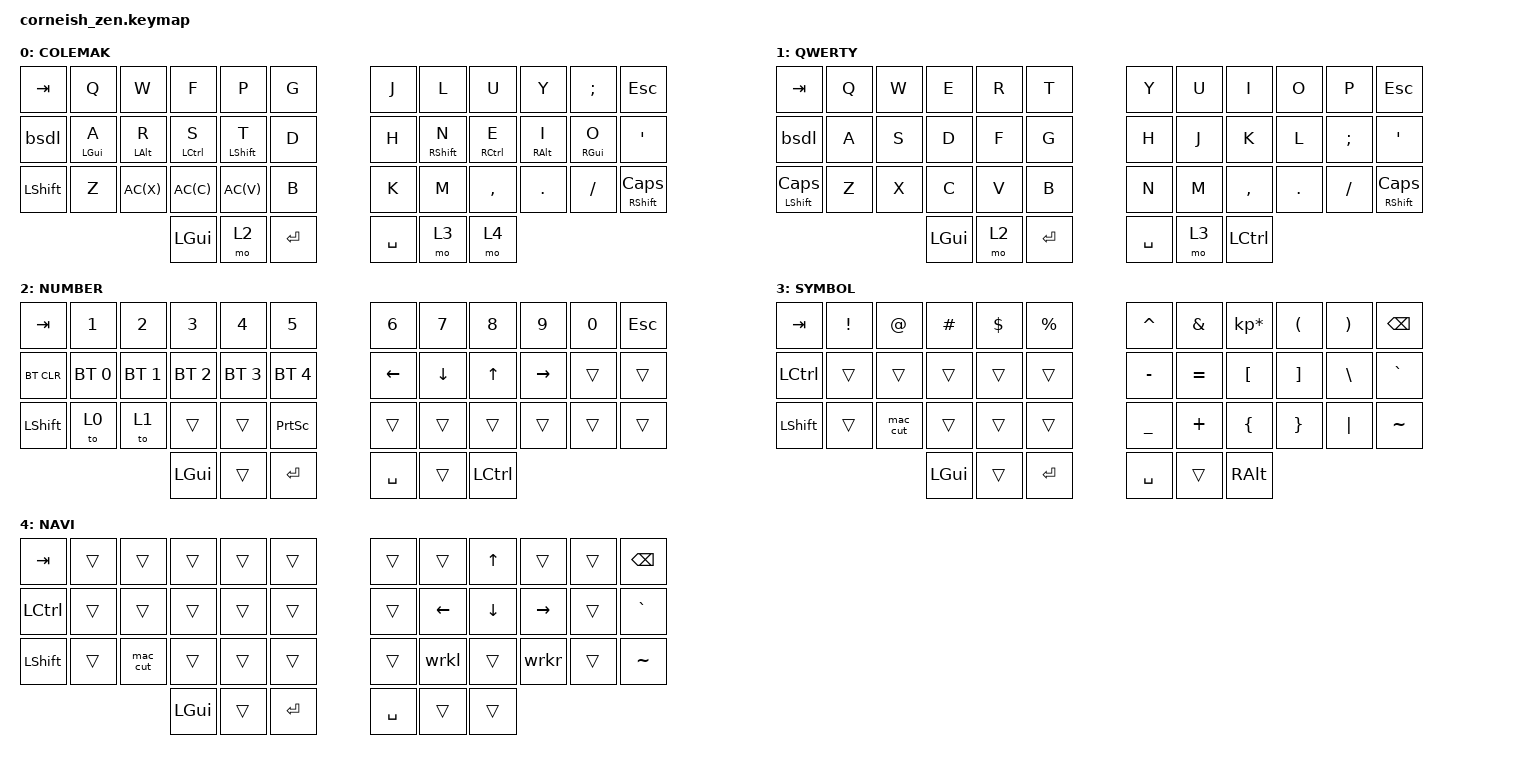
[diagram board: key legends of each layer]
#include <behaviors.dtsi>
#include <dt-bindings/zmk/keys.h>
#include <dt-bindings/zmk/bt.h>

/ {
  chosen {
    zmk,matrix_transform = &default_transform;
    //zmk,matrix_transform = &five_column_transform;
  };
};

#define COLEMAK 0
#define QWERTY 	1
#define NUMBER	2
#define SYMBOL	3

#define AC(keycode) &ac LC(keycode) keycode

/{
	macros {
		ZMK_MACRO(mac_cut,
			wait-ms = <40>;
			tap-ms = <20>;
			bindings = <&macro_press &kp LCTRL>, <&macro_tap &kp X>, <&macro_release &kp LCTRL>;
		)
		ZMK_MACRO(wrkl,
			wait-ms = <40>;
			tap-ms = <20>;
			bindings = <&macro_press &kp LGUI &kp LCTRL>, <&macro_tap &kp LEFT>, <&macro_release &kp LGUI &kp LCTRL>;
		)
		ZMK_MACRO(wrkr,
			wait-ms = <40>;
			tap-ms = <20>;
			bindings = <&macro_press &kp LGUI &kp LCTRL>, <&macro_tap &kp RIGHT>, <&macro_release &kp LGUI &kp LCTRL>;
		)
	};
};
			
/ {
    behaviors {
        bsdl: bspc_del {
            compatible = "zmk,behavior-mod-morph";
            label = "BSPC_DEL";
            #binding-cells = <0>;
            bindings = <&kp BSPC>, <&kp DEL>;
            mods = <(MOD_LSFT|MOD_RSFT)>;
			keep-mods = <(MOD_RSFT)>;
        };
		gqt: global-quick-tap {
			compatible = "zmk,behavior-hold-tap";
			label = "GLOBAL_QUICK_TAP";
			#binding-cells = <2>;
			flavor = "tap-preferred";
			tapping-term-ms = <200>;
			quick-tap-ms = <125>;
			global-quick-tap;
			bindings = <&kp>, <&kp>;
		};
		ac: Auto-control {
			compatible = "zmk,behavior-hold-tap";
			label = "AUTO_CTRL";
			#binding-cells = <2>;
			flavor = "tap-preferred";
			tapping-term-ms = <300>;
			quick-tap-ms = <0>;
			global-quick-tap;
			bindings = <&kp>, <&kp>;
		};
        hm: homerow_mods {
            compatible = "zmk,behavior-hold-tap";
            label = "HOMEROW_MODS";
            #binding-cells = <2>;
            tapping-term-ms = <380>;
            quick-tap-ms = <0>;
            flavor = "tap-preferred";
            bindings = <&kp>, <&kp>;
        };
	};
};

/ {
        keymap {
                compatible = "zmk,keymap";

                default_layer {
                        label = "COLEMAK";
// -----------------------------------------------------------------------------------------
// |  TAB |  Q  |  W  |  F  |  P  |  G  |   |  J  |  L   |  U  |  Y  |  ;  | ESC |
// | CTRL |  A  |  R  |  S  |  T  |  D  |   |  H  |  N   |  E  |  I  |  O  |  '   |
// | SHFT |  Z  |  X  |  C  |  V  |  B  |   |  K  |  M   |  ,  |  .  |  /  | SHFT  |
//                    | GUI | LWR | SPC |   | ENT | RSE  | CTL |
                        bindings = <
   &kp TAB   		&kp Q 			&kp W 			&kp F 			&kp P 			&kp G  			&kp J 			&kp L  		&kp U     	&kp Y   	&kp SEMI   	&kp ESC
   &bsdl		&hm LGUI A		&hm LALT R		&hm LCTRL S		&hm LSHFT T		&kp D   		&kp H 			&hm RSHFT N 	&hm RCTRL E	&hm RALT I 	&hm RGUI O	&kp SQT
   &kp LSHFT	 	&kp Z 			AC(X)			AC(C)			AC(V)			&kp B   		&kp K 			&kp M  		&kp COMMA 	&kp DOT 	&kp FSLH 	&mt RSHFT CAPS
													&kp LGUI 		&mo 2 			&kp RET   		&kp SPACE 		&mo 3 		&mo 4
                        >;
                };
				
                qwerty_layer {
                        label = "QWERTY";
// -----------------------------------------------------------------------------------------
// |  TAB |  Q  |  W  |  E  |  R  |  T  |   |  Y  |  U   |  I  |  O  |  P  | ESC |
// | CTRL |  A  |  S  |  D  |  F  |  G  |   |  H  |  J   |  K  |  L  |  ;  |  '   |
// | SHFT |  Z  |  X  |  C  |  V  |  B  |   |  N  |  M   |  ,  |  .  |  /  | SHFT  |
//                    | GUI | LWR | SPC |   | ENT | RSE  | CTL |
                        bindings = <
   &kp TAB   		&kp Q 			&kp W 			&kp E 			&kp R 			&kp T   		&kp Y 			&kp U  		&kp I     	&kp O   	&kp P    	&kp ESC
   &bsdl 		&kp A 			&kp S 			&kp D 			&kp F 			&kp G   		&kp H 			&kp J  		&kp K     	&kp L   	&kp SEMI 	&kp SQT
   &mt LSHFT CAPS 	&kp Z 			&kp X 			&kp C 			&kp V 			&kp B   		&kp N 			&kp M  		&kp COMMA 	&kp DOT 	&kp FSLH 	&mt RSHFT CAPS
									&kp LGUI 		&mo 2 			&kp RET   		&kp SPACE 		&mo 3 		&kp LCTRL
                        >;
                };
				
                lower_layer {
                        label = "NUMBER";
// -----------------------------------------------------------------------------------------
// |  TAB |  1  |  2  |  3  |  4  |  5  |   |  6  |  7  |  8  |  9  |  0  | ESC |
// | BTCLR| BT1 | BT2 | BT3 | BT4 | BT5 |   | LFT | DWN |  UP | RGT |     |      |
// | SHFT |CLMK | QWE |     |     | PRSC|   |     |     |     |     |     |      |
//                    | GUI |     | SPC |   | ENT |     | CTL |
                        bindings = <
   &kp TAB    		&kp N1       	&kp N2       	&kp N3       	&kp N4       	&kp N5         	&kp N6   	&kp N7   	&kp N8 		&kp N9    	&kp N0 		&kp ESC
   &bt BT_CLR 		&bt BT_SEL 0 	&bt BT_SEL 1 	&bt BT_SEL 2 	&bt BT_SEL 3 	&bt BT_SEL 4   	&kp LEFT 	&kp DOWN 	&kp UP 		&kp RIGHT 	&trans 		&trans
   &kp LSHFT  		&to 0		&to 1		&trans       	&trans       	&kp PSCRN      	&trans   	&trans   	&trans 		&trans    	&trans 		&trans
							&kp LGUI     	&trans       	&kp RET      	&kp SPACE  	&trans   	&kp LCTRL
                        >;
                };

                raise_layer {
                        label = "SYMBOL";
// -----------------------------------------------------------------------------------------
// |  TAB |  !  |  @  |  #  |  $  |  %  |   |  ^  |  &  |  *  |  (  |  )  | BKSP |
// | CTRL |     |     |     |     |     |   |  -  |  =  |  [  |  ]  |  \  |  `   |
// | SHFT |     | CUT |     |     |     |   |  _  |  +  |  {  |  }  | "|" |  ~   |
//                    | GUI |     | SPC |   | ENT |     | CTL |
                        bindings = <
   &kp  TAB  		&kp EXCL 	&kp AT 		&kp HASH 	&kp DLLR &kp PRCNT   		&kp CARET &kp AMPS  &kp KP_MULTIPLY &kp LPAR &kp RPAR &kp BSPC
   &kp LCTRL 		&trans   	&trans 		&trans   	&trans   &trans      		&kp MINUS &kp EQUAL &kp LBKT        &kp RBKT &kp BSLH &kp GRAVE
   &kp LSHFT 		&trans   	&mac_cut 	&trans   	&trans   &trans      		&kp UNDER &kp PLUS  &kp LBRC        &kp RBRC &kp PIPE &kp TILDE
                    	     				&kp LGUI 	&trans   &kp RET   		&kp SPACE   &trans    &kp RALT
                        >;
                };

		nav_layer {
                        label = "NAVI";
// -----------------------------------------------------------------------------------------
// |  TAB |     |     |     |     |     |   |       |  UP   |  *     |  (  |  )  | BKSP |
// | CTRL |     |     |     |     |     |   |  LFT  |  DWN  |  RGT   |  ]  |  \  |  `   |
// | SHFT |     | CUT |     |     |     |   | wrk<  |  +    |  wrk>  |  }  | "|" |  ~   |
//                    | GUI |     | SPC |   | ENT |     | CTL |
                        bindings = <
   &kp  TAB  		&trans		&trans 		&trans	 	&trans	 &trans	     		&trans		&trans	 	&kp UP 		&trans		&trans		&kp BSPC
   &kp LCTRL 		&trans   	&trans 		&trans   	&trans   &trans      		&trans		&kp LEFT 	&kp DOWN        &kp RIGHT 	&trans		&kp GRAVE
   &kp LSHFT 		&trans   	&mac_cut 	&trans   	&trans   &trans      		&trans		&wrkl	  	&trans	        &wrkr 		&trans	 	&kp TILDE
                					&kp LGUI 	&trans   &kp RET   		&kp SPACE      	&trans    	&trans
                        >;
                };
        };
};
